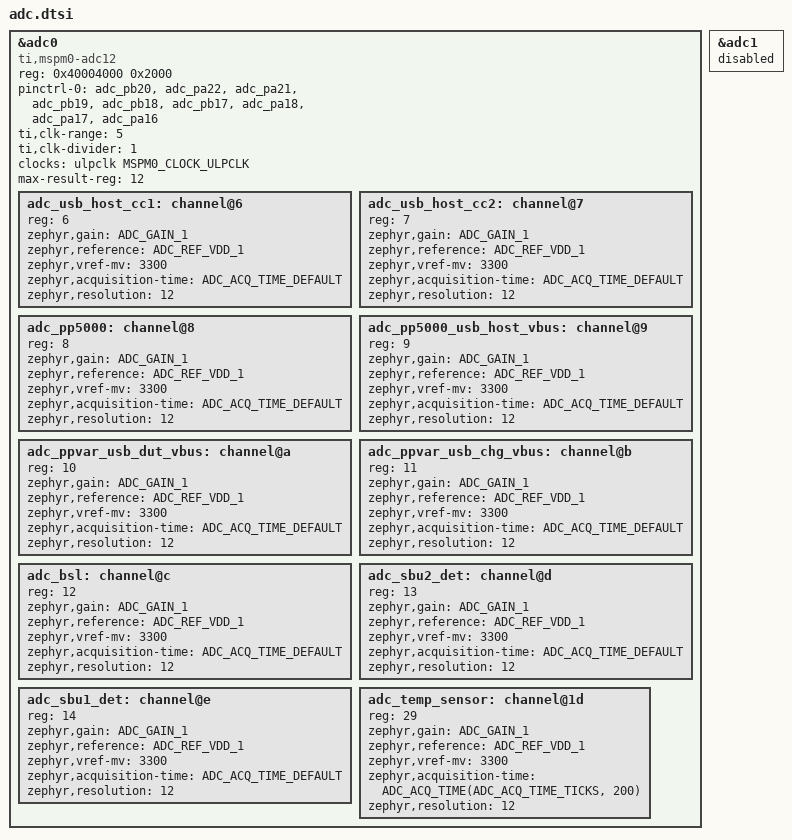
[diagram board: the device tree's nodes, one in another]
/* Copyright 2026 The ChromiumOS Authors
 * Use of this source code is governed by a BSD-style license that can be
 * found in the LICENSE file.
 */

#include <zephyr/dt-bindings/adc/adc.h>

&adc0 {
	compatible = "ti,mspm0-adc12";
	reg = <0x40004000 0x2000>;
	status = "okay";
	#address-cells = <1>;
	#size-cells = <0>;

	pinctrl-0 = <&adc_pb20 &adc_pa22 &adc_pa21 &adc_pb19 &adc_pb18 &adc_pb17 &adc_pa18 &adc_pa17 &adc_pa16>;
	pinctrl-names = "default";
	ti,clk-range = <5>;
	ti,clk-divider = <1>;

	clocks = <&ulpclk MSPM0_CLOCK_ULPCLK>;
	max-result-reg = <12>;

	adc_usb_host_cc1: channel@6 {
		reg = <6>;
		zephyr,gain = "ADC_GAIN_1";
		zephyr,reference = "ADC_REF_VDD_1";
		zephyr,vref-mv = <3300>;
		zephyr,acquisition-time = <ADC_ACQ_TIME_DEFAULT>;
		zephyr,resolution = <12>;
	};

	adc_usb_host_cc2: channel@7 {
		reg = <7>;
		zephyr,gain = "ADC_GAIN_1";
		zephyr,reference = "ADC_REF_VDD_1";
		zephyr,vref-mv = <3300>;
		zephyr,acquisition-time = <ADC_ACQ_TIME_DEFAULT>;
		zephyr,resolution = <12>;
	};

	adc_pp5000: channel@8 {
		reg = <8>;
		zephyr,gain = "ADC_GAIN_1";
		zephyr,reference = "ADC_REF_VDD_1";
		zephyr,vref-mv = <3300>;
		zephyr,acquisition-time = <ADC_ACQ_TIME_DEFAULT>;
		zephyr,resolution = <12>;
	};

	adc_pp5000_usb_host_vbus: channel@9 {
		reg = <9>;
		zephyr,gain = "ADC_GAIN_1";
		zephyr,reference = "ADC_REF_VDD_1";
		zephyr,vref-mv = <3300>;
		zephyr,acquisition-time = <ADC_ACQ_TIME_DEFAULT>;
		zephyr,resolution = <12>;
	};

	adc_ppvar_usb_dut_vbus: channel@a {
		reg = <10>;
		zephyr,gain = "ADC_GAIN_1";
		zephyr,reference = "ADC_REF_VDD_1";
		zephyr,vref-mv = <3300>;
		zephyr,acquisition-time = <ADC_ACQ_TIME_DEFAULT>;
		zephyr,resolution = <12>;
	};

	adc_ppvar_usb_chg_vbus: channel@b {
		reg = <11>;
		zephyr,gain = "ADC_GAIN_1";
		zephyr,reference = "ADC_REF_VDD_1";
		zephyr,vref-mv = <3300>;
		zephyr,acquisition-time = <ADC_ACQ_TIME_DEFAULT>;
		zephyr,resolution = <12>;
	};

	adc_bsl: channel@c {
		reg = <12>;
		zephyr,gain = "ADC_GAIN_1";
		zephyr,reference = "ADC_REF_VDD_1";
		zephyr,vref-mv = <3300>;
		zephyr,acquisition-time = <ADC_ACQ_TIME_DEFAULT>;
		zephyr,resolution = <12>;
	};

	adc_sbu2_det: channel@d {
		reg = <13>;
		zephyr,gain = "ADC_GAIN_1";
		zephyr,reference = "ADC_REF_VDD_1";
		zephyr,vref-mv = <3300>;
		zephyr,acquisition-time = <ADC_ACQ_TIME_DEFAULT>;
		zephyr,resolution = <12>;
	};

	adc_sbu1_det: channel@e {
		reg = <14>;
		zephyr,gain = "ADC_GAIN_1";
		zephyr,reference = "ADC_REF_VDD_1";
		zephyr,vref-mv = <3300>;
		zephyr,acquisition-time = <ADC_ACQ_TIME_DEFAULT>;
		zephyr,resolution = <12>;
	};

	adc_temp_sensor: channel@1d {
		reg = <29>;
		zephyr,gain = "ADC_GAIN_1";
		zephyr,reference = "ADC_REF_VDD_1";
		zephyr,vref-mv = <3300>;
		zephyr,acquisition-time =
			<ADC_ACQ_TIME(ADC_ACQ_TIME_TICKS, 200)>;
		zephyr,resolution = <12>;
	};
};

&adc1 {
	status = "disabled";
};
